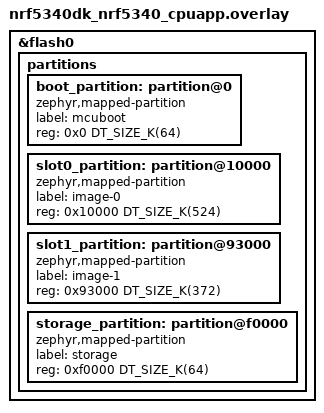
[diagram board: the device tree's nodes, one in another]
/*
 * Copyright (c) 2026 Nordic Semiconductor ASA
 *
 * SPDX-License-Identifier: LicenseRef-Nordic-5-Clause
 */

/* Pin the flash map (via DTS, no Partition Manager) to the NCS v3.2 layout so
 * the overwrite-only update image is accepted by an NCS v3.2 MCUboot: primary
 * slot ends at 0x93000, placing the secondary slot at 0x93000.
 */
/delete-node/ &boot_partition;
/delete-node/ &slot0_partition;
/delete-node/ &slot1_partition;
/delete-node/ &storage_partition;

&flash0 {
	partitions {
		ranges;
		#address-cells = <1>;
		#size-cells = <1>;

		boot_partition: partition@0 {
			compatible = "zephyr,mapped-partition";
			label = "mcuboot";
			reg = <0x0 DT_SIZE_K(64)>;
		};

		slot0_partition: partition@10000 {
			compatible = "zephyr,mapped-partition";
			label = "image-0";
			reg = <0x10000 DT_SIZE_K(524)>;
		};

		slot1_partition: partition@93000 {
			compatible = "zephyr,mapped-partition";
			label = "image-1";
			reg = <0x93000 DT_SIZE_K(372)>;
		};

		storage_partition: partition@f0000 {
			compatible = "zephyr,mapped-partition";
			label = "storage";
			reg = <0xf0000 DT_SIZE_K(64)>;
		};
	};
};
